# nrf54l15_application register map
Vendor: Nordic Semiconductor; Series: nrf54l; File version: 1
CPU: CM33 r0p4, little endian, MPU, FPU, 3 interrupt priority bits, 270 interrupts, 4 SAU regions
Registers are 32-bit, read-write, reset 0x0 unless marked. A register's access mark holds for its fields unless they carry their own. Offsets are from the block's base; [hi:lo] are bit positions; lines under a group give offsets from that group; {n}, {i} and the like mark numbered series; 'fields as' and 'values as' point back to an identical list.

## GLOBAL_UICR_S — User Information Configuration Registers
Base 0x00FFD000
{0x0+0x20*i} APPROTECT[{i}] (i=0..0) group — Access Port Protection Registers
  0x00 PROTECT0 rw-once reset 0xFFFFFFFF — Description cluster: Access port protection
    [31:0] PALL
      0xFFFFFFFF=Unprotected (Leaves TAMPC PROTECT.DOMAIN DBGEN and NIDEN signal protectors unlocked and under CPU control.)
  0x1C PROTECT1 rw-once reset 0xFFFFFFFF — Description cluster: Access port protection
    fields as APPROTECT[0].PROTECT0
{0x20+0x20*i} SECUREAPPROTECT[{i}] (i=0..0) group — Access Port Protection Registers
  0x00 PROTECT0 rw-once reset 0xFFFFFFFF — Description cluster: Access port protection
    [31:0] PALL
      0xFFFFFFFF=Unprotected (Leaves TAMPC PROTECT.DOMAIN SPIDEN and SPNIDEN signal protectors unlocked and under CPU control.)
  0x1C PROTECT1 rw-once reset 0xFFFFFFFF — Description cluster: Access port protection register
    fields as SECUREAPPROTECT[0].PROTECT0
{0x40+0x20*i} AUXAPPROTECT[{i}] (i=0..0) group — Access Port Protection Registers
  0x00 PROTECT0 rw-once reset 0xFFFFFFFF — Description cluster: Access port protection
    [31:0] PALL
      0xFFFFFFFF=Unprotected (Leaves TAMPC PROTECT.AP DBGEN and SPIDEN signal protectors unlocked and under CPU control.)
  0x1C PROTECT1 rw-once reset 0xFFFFFFFF — Description cluster: Access port protection register
    fields as AUXAPPROTECT[0].PROTECT0
{0x60+0x20*i} ERASEPROTECT[{i}] (i=0..0) group — Erase Protection Registers
  0x00 PROTECT0 rw-once reset 0xFFFFFFFF — Description cluster: Erase protection
    [31:0] PALL
      0xFFFFFFFF=Unprotected (The device can be erased using the CTRL-AP Erase all function and TAMPC PROTECT.ERASEPROTECT signal protector is unlocked.)
  0x1C PROTECT1 rw-once reset 0xFFFFFFFF — Description cluster: Erase protection
    [31:0] PALL
      0xFFFFFFFF=Unprotected (The device canbe erased using the CTRL-AP Erase all function and TAMPC PROTECT.ERASEPROTECT signal protector is unlocked.)
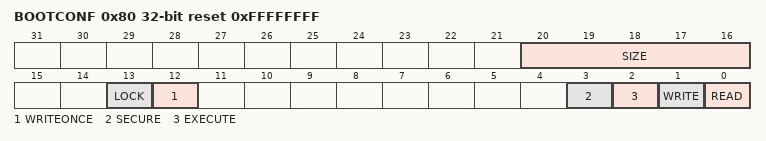
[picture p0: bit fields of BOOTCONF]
0x80 BOOTCONF rw-once reset 0xFFFFFFFF — Immutable boot region configuration.
  [20:16] SIZE — Immutable boot region size
  [13] LOCK — Enable lock of configuration register
    0=Disabled (Lock is disabled, and the RRAMC region configuration registers for the immutable boot region are writable.); 1=Enabled (Lock is enabled, and the RRAMC configuration registers for the immutable boot region are read-only.)
  [12] WRITEONCE
    0=Disabled (Write-once disabled); 1=Enabled (Write-once enabled)
  [3] SECURE — Secure access
    0=NonSecure (Both secure and non-secure access to region is allowed); 1=Secure (Only secure access to region is allowed)
  [2] EXECUTE — Execute access
    0=NotAllowed (Executing code from the region is not allowed); 1=Allowed (Executing code from the region is allowed)
  [1] WRITE — Write access
    0=NotAllowed (Writing to the region is not allowed); 1=Allowed (Writing to the region is allowed)
  [0] READ — Read access
    0=NotAllowed (Reading from the region is not allowed); 1=Allowed (Reading from the region is allowed)
0x200 USER group — Unspecified
  0x00 ROT group — Assets installed to establish initial Root of Trust in the device.
    {0x0+0x2C*k} PUBKEY[{k}] (k=0..3) group — Unspecified
      {0x0+4l} DIGEST[{l}] (l=0..7) rw-once reset 0xFFFFFFFF — Description collection: First 256 bits of SHA2-512 digest over RoT public key generation [n].
        [31:0] VALUE — Value for word [o] in the key digest [n].
      {0x20+4l} REVOKE[{l}] (l=0..2) rw-once reset 0xFFFFFFFF — Description collection: Revocation status for RoT public key generation [n].
        [31:0] STATUS — Revocation status.
          0xFFFFFFFF=NotRevoked (Key not revoked.)
    {0xB0+0x2C*k} AUTHOPKEY[{k}] (k=0..3) group — Unspecified
      {0x0+4l} DIGEST[{l}] (l=0..7) rw-once reset 0xFFFFFFFF — Description collection: First 256 bits of SHA2-512 digest over RoT authenticated operation public key generation [n].
        [31:0] VALUE — Value for word [o] in the key digest [n].
      {0x20+4l} REVOKE[{l}] (l=0..2) rw-once reset 0xFFFFFFFF — Description collection: Revocation status for RoT authenticated operation public key generation [n].
        fields as USER.ROT.PUBKEY[0].REVOKE[0]
{0x500+4i} OTP[{i}] (i=0..319) rw-once reset 0xFFFFFFFF — Description collection: One time programmable memory
  [31:0] OTP — OTP word

## Notices in the file
Copyright (c) 2010 - 2024, Nordic Semiconductor ASA All rights reserved.
SPDX-License-Identifier: BSD-3-Clause
Redistribution and use in source and binary forms, with or without
modification, are permitted provided that the following conditions are met:
1. Redistributions of source code must retain the above copyright notice, this
list of conditions and the following disclaimer.
2. Redistributions in binary form must reproduce the above copyright
notice, this list of conditions and the following disclaimer in the
documentation and/or other materials provided with the distribution.
3. Neither the name of Nordic Semiconductor ASA nor the names of its
contributors may be used to endorse or promote products derived from this
software without specific prior written permission.
THIS SOFTWARE IS PROVIDED BY THE COPYRIGHT HOLDERS AND CONTRIBUTORS "AS IS"
AND ANY EXPRESS OR IMPLIED WARRANTIES, INCLUDING, BUT NOT LIMITED TO, THE
IMPLIED WARRANTIES OF MERCHANTABILITY, AND FITNESS FOR A PARTICULAR PURPOSE
ARE DISCLAIMED. IN NO EVENT SHALL NORDIC SEMICONDUCTOR ASA OR CONTRIBUTORS BE
LIABLE FOR ANY DIRECT, INDIRECT, INCIDENTAL, SPECIAL, EXEMPLARY, OR
CONSEQUENTIAL DAMAGES (INCLUDING, BUT NOT LIMITED TO, PROCUREMENT OF
SUBSTITUTE GOODS OR SERVICES; LOSS OF USE, DATA, OR PROFITS; OR BUSINESS
INTERRUPTION) HOWEVER CAUSED AND ON ANY THEORY OF LIABILITY, WHETHER IN
CONTRACT, STRICT LIABILITY, OR TORT (INCLUDING NEGLIGENCE OR OTHERWISE)
ARISING IN ANY WAY OUT OF THE USE OF THIS SOFTWARE, EVEN IF ADVISED OF THE
POSSIBILITY OF SUCH DAMAGE.
